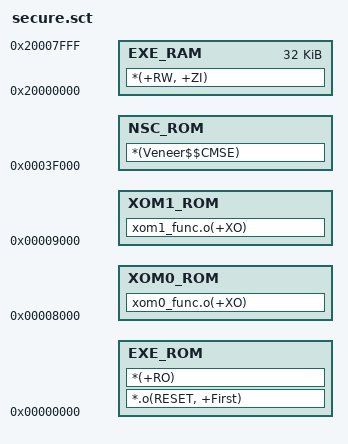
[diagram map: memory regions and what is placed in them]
    
LR_ROM 0x0 0x10000
{

    EXE_ROM +0
    {
        *.o(RESET, +First)
        *(+RO)
    }
    
    EXE_RAM 0x20000000 0x8000
    {
        *(+RW, +ZI)
    }
	
}

LR_NSC 0x3f000 0x800
{
    NSC_ROM +0
    {
        *(Veneer$$CMSE)
    }
}


LR_XOM0 0x8000 0x1000
{
    XOM0_ROM +0
    {
        xom0_func.o(+XO)
    }
}

LR_XOM1 0x9000 0x1000
{
    XOM1_ROM +0
    {
        xom1_func.o(+XO)
    }
}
